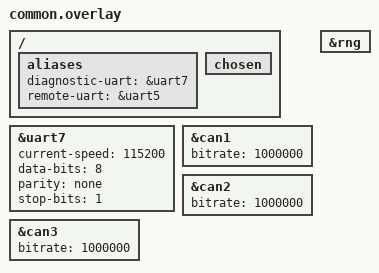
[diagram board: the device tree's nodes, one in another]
/* Installed MC02 baseline, based on the current vehicle overlays. */
/ {
    aliases {
        diagnostic-uart = &uart7;
        remote-uart = &uart5;
        /delete-property/ referee-uart;
        /delete-property/ telemetry-uart;
    };

    chosen {
        /delete-property/ zephyr,console;
        /delete-property/ zephyr,shell-uart;
    };
};

&uart7 {
    status = "okay";
    current-speed = <115200>;
    data-bits = <8>;
    parity = "none";
    stop-bits = "1";
};

&can1 {
    status = "okay";
    bitrate = <1000000>;
};

&can2 {
    status = "okay";
    bitrate = <1000000>;
};

&can3 {
    status = "okay";
    bitrate = <1000000>;
};

&rng {
    status = "okay";
};
